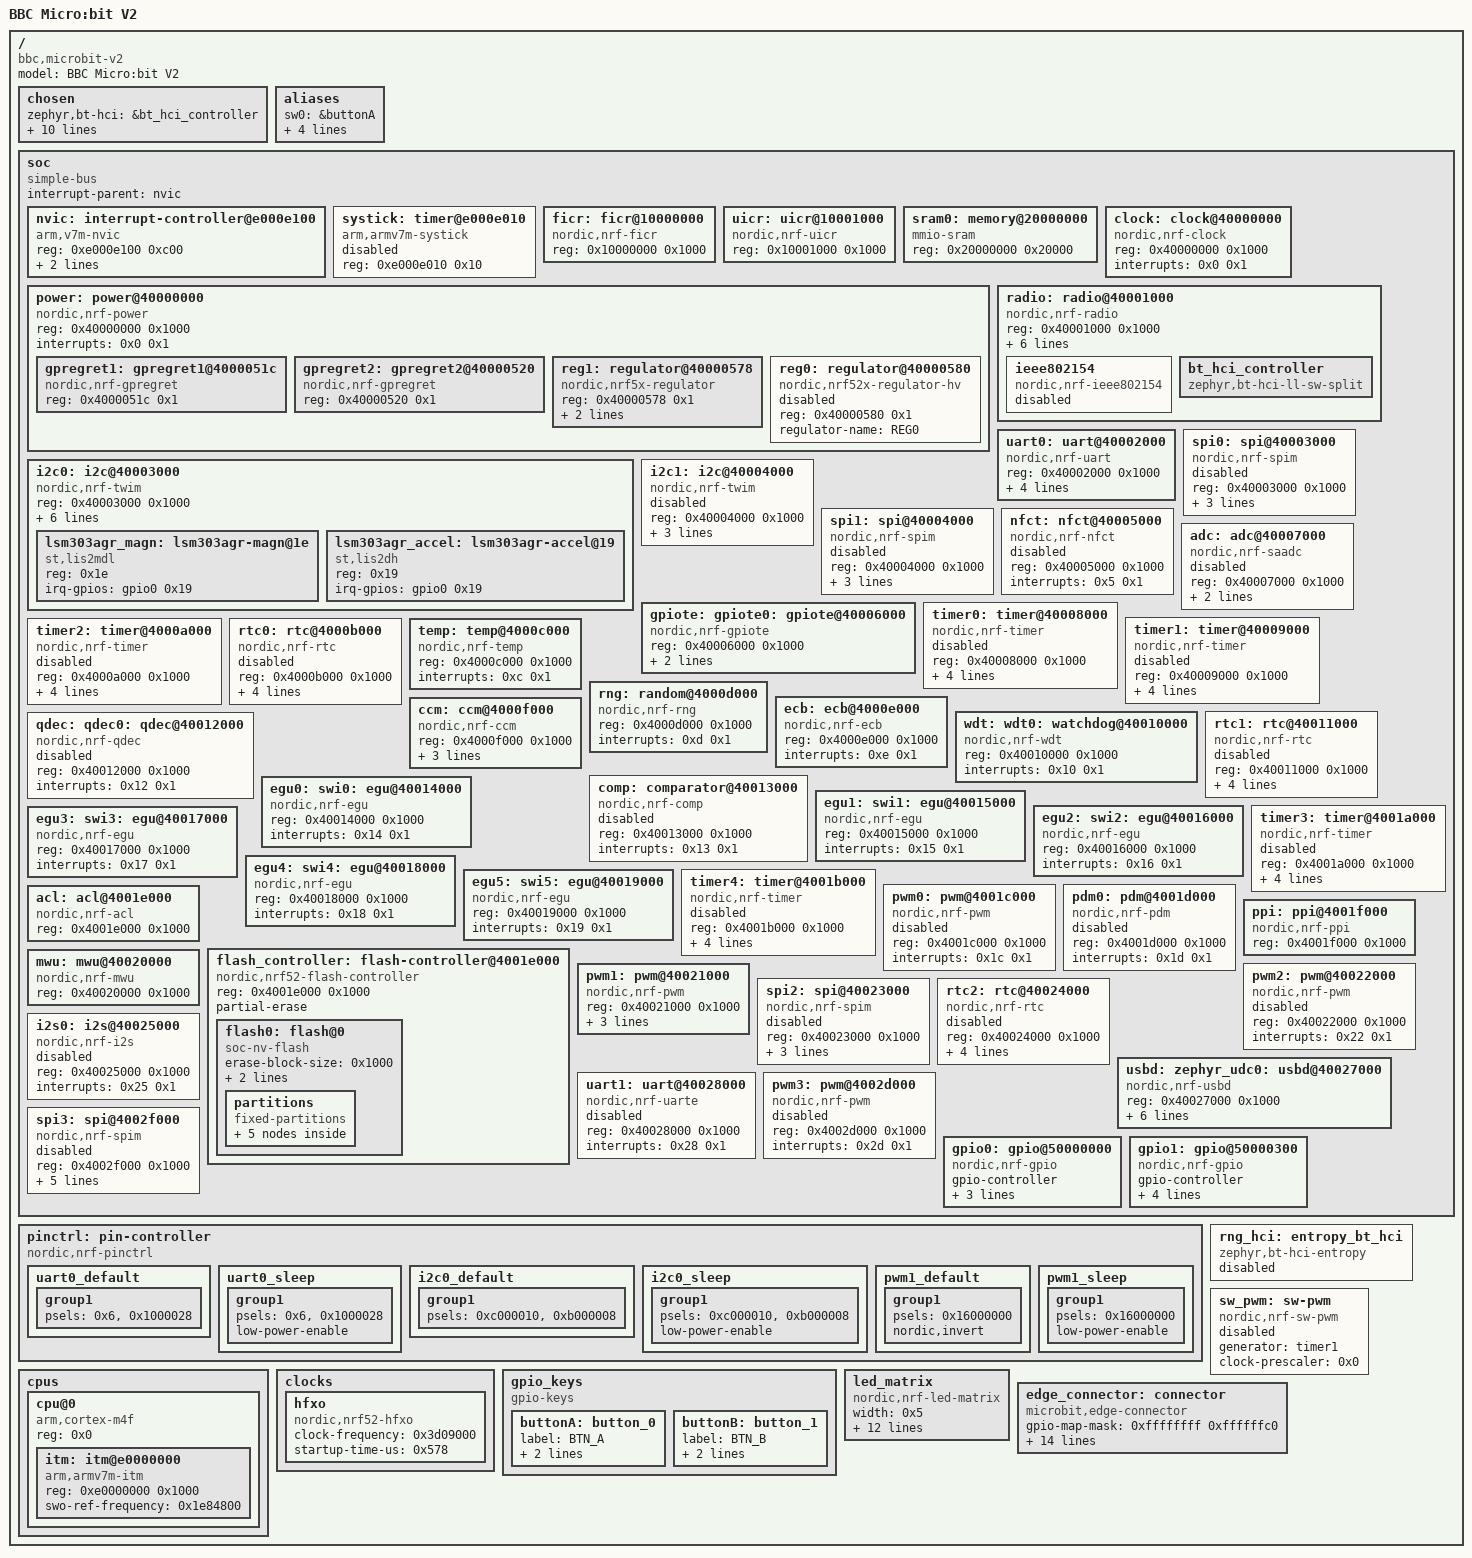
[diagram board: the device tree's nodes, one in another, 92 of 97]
/dts-v1/;

/* node '/' defined in zephyr/dts/common/skeleton.dtsi:9 */
/ {
	#address-cells = < 0x1 >;       /* in zephyr/dts/common/skeleton.dtsi:10 */
	#size-cells = < 0x1 >;          /* in zephyr/dts/common/skeleton.dtsi:11 */
	model = "BBC Micro:bit V2";     /* in zephyr/boards/bbc/microbit_v2/bbc_microbit_v2.dts:13 */
	compatible = "bbc,microbit-v2"; /* in zephyr/boards/bbc/microbit_v2/bbc_microbit_v2.dts:14 */

	/* node '/chosen' defined in zephyr/dts/common/skeleton.dtsi:13 */
	chosen {
		zephyr,bt-hci = &bt_hci_controller;          /* in zephyr/dts/arm/nordic/nrf52833.dtsi:14 */
		zephyr,entropy = &rng;                       /* in zephyr/dts/arm/nordic/nrf52833.dtsi:15 */
		zephyr,flash-controller = &flash_controller; /* in zephyr/dts/arm/nordic/nrf52833.dtsi:16 */
		zephyr,console = &uart0;                     /* in zephyr/boards/bbc/microbit_v2/bbc_microbit_v2.dts:26 */
		zephyr,shell-uart = &uart0;                  /* in zephyr/boards/bbc/microbit_v2/bbc_microbit_v2.dts:27 */
		zephyr,bt-mon-uart = &uart0;                 /* in zephyr/boards/bbc/microbit_v2/bbc_microbit_v2.dts:28 */
		zephyr,bt-c2h-uart = &uart0;                 /* in zephyr/boards/bbc/microbit_v2/bbc_microbit_v2.dts:29 */
		zephyr,sram = &sram0;                        /* in zephyr/boards/bbc/microbit_v2/bbc_microbit_v2.dts:30 */
		zephyr,flash = &flash0;                      /* in zephyr/boards/bbc/microbit_v2/bbc_microbit_v2.dts:31 */
		zephyr,code-partition = &slot0_partition;    /* in zephyr/boards/bbc/microbit_v2/bbc_microbit_v2.dts:32 */
		zephyr,display = &led_matrix;                /* in zephyr/boards/bbc/microbit_v2/bbc_microbit_v2.dts:33 */
	};

	/* node '/aliases' defined in zephyr/dts/common/skeleton.dtsi:15 */
	aliases {
		sw0 = &buttonA;            /* in zephyr/boards/bbc/microbit_v2/bbc_microbit_v2.dts:18 */
		sw1 = &buttonB;            /* in zephyr/boards/bbc/microbit_v2/bbc_microbit_v2.dts:19 */
		magn0 = &lsm303agr_magn;   /* in zephyr/boards/bbc/microbit_v2/bbc_microbit_v2.dts:20 */
		accel0 = &lsm303agr_accel; /* in zephyr/boards/bbc/microbit_v2/bbc_microbit_v2.dts:21 */
		watchdog0 = &wdt0;         /* in zephyr/boards/bbc/microbit_v2/bbc_microbit_v2.dts:22 */
	};

	/* node '/soc' defined in zephyr/dts/arm/armv7-m.dtsi:6 */
	soc {
		#address-cells = < 0x1 >;     /* in zephyr/dts/arm/armv7-m.dtsi:7 */
		#size-cells = < 0x1 >;        /* in zephyr/dts/arm/armv7-m.dtsi:8 */
		interrupt-parent = < &nvic >; /* in zephyr/dts/arm/armv7-m.dtsi:10 */
		ranges;                       /* in zephyr/dts/arm/armv7-m.dtsi:11 */
		compatible = "simple-bus";    /* in zephyr/dts/arm/nordic/nrf52833_qiaa.dtsi:21 */

		/* node '/soc/interrupt-controller@e000e100' defined in zephyr/dts/arm/armv7-m.dtsi:13 */
		nvic: interrupt-controller@e000e100 {
			#address-cells = < 0x1 >;            /* in zephyr/dts/arm/armv7-m.dtsi:14 */
			compatible = "arm,v7m-nvic";         /* in zephyr/dts/arm/armv7-m.dtsi:15 */
			reg = < 0xe000e100 0xc00 >;          /* in zephyr/dts/arm/armv7-m.dtsi:16 */
			interrupt-controller;                /* in zephyr/dts/arm/armv7-m.dtsi:17 */
			#interrupt-cells = < 0x2 >;          /* in zephyr/dts/arm/armv7-m.dtsi:18 */
			arm,num-irq-priority-bits = < 0x3 >; /* in zephyr/dts/arm/nordic/nrf52833.dtsi:577 */
			phandle = < 0x1 >;                   /* in zephyr/dts/arm/armv7-m.dtsi:10 */
		};

		/* node '/soc/timer@e000e010' defined in zephyr/dts/arm/armv7-m.dtsi:21 */
		systick: timer@e000e010 {
			compatible = "arm,armv7m-systick"; /* in zephyr/dts/arm/armv7-m.dtsi:22 */
			reg = < 0xe000e010 0x10 >;         /* in zephyr/dts/arm/armv7-m.dtsi:23 */
			status = "disabled";               /* in zephyr/dts/arm/nordic/nrf52833.dtsi:582 */
		};

		/* node '/soc/ficr@10000000' defined in zephyr/dts/arm/nordic/nrf52833.dtsi:48 */
		ficr: ficr@10000000 {
			compatible = "nordic,nrf-ficr"; /* in zephyr/dts/arm/nordic/nrf52833.dtsi:49 */
			reg = < 0x10000000 0x1000 >;    /* in zephyr/dts/arm/nordic/nrf52833.dtsi:50 */
			#nordic,ficr-cells = < 0x1 >;   /* in zephyr/dts/arm/nordic/nrf52833.dtsi:51 */
			status = "okay";                /* in zephyr/dts/arm/nordic/nrf52833.dtsi:52 */
		};

		/* node '/soc/uicr@10001000' defined in zephyr/dts/arm/nordic/nrf52833.dtsi:55 */
		uicr: uicr@10001000 {
			compatible = "nordic,nrf-uicr"; /* in zephyr/dts/arm/nordic/nrf52833.dtsi:56 */
			reg = < 0x10001000 0x1000 >;    /* in zephyr/dts/arm/nordic/nrf52833.dtsi:57 */
			status = "okay";                /* in zephyr/dts/arm/nordic/nrf52833.dtsi:58 */
		};

		/* node '/soc/memory@20000000' defined in zephyr/dts/arm/nordic/nrf52833.dtsi:61 */
		sram0: memory@20000000 {
			compatible = "mmio-sram";            /* in zephyr/dts/arm/nordic/nrf52833.dtsi:62 */
			#address-cells = < 0x1 >;            /* in zephyr/dts/arm/nordic/nrf52833.dtsi:63 */
			#size-cells = < 0x1 >;               /* in zephyr/dts/arm/nordic/nrf52833.dtsi:64 */
			reg = < 0x20000000 0x20000 >;        /* in zephyr/dts/arm/nordic/nrf52833_qiaa.dtsi:15 */
			ranges = < 0x0 0x20000000 0x20000 >; /* in zephyr/dts/arm/nordic/nrf52833_qiaa.dtsi:16 */
		};

		/* node '/soc/clock@40000000' defined in zephyr/dts/arm/nordic/nrf52833.dtsi:67 */
		clock: clock@40000000 {
			compatible = "nordic,nrf-clock"; /* in zephyr/dts/arm/nordic/nrf52833.dtsi:68 */
			reg = < 0x40000000 0x1000 >;     /* in zephyr/dts/arm/nordic/nrf52833.dtsi:69 */
			interrupts = < 0x0 0x1 >;        /* in zephyr/dts/arm/nordic/nrf52833.dtsi:70 */
			status = "okay";                 /* in zephyr/dts/arm/nordic/nrf52833.dtsi:71 */
		};

		/* node '/soc/power@40000000' defined in zephyr/dts/arm/nordic/nrf52833.dtsi:74 */
		power: power@40000000 {
			compatible = "nordic,nrf-power"; /* in zephyr/dts/arm/nordic/nrf52833.dtsi:75 */
			reg = < 0x40000000 0x1000 >;     /* in zephyr/dts/arm/nordic/nrf52833.dtsi:76 */
			interrupts = < 0x0 0x1 >;        /* in zephyr/dts/arm/nordic/nrf52833.dtsi:77 */
			status = "okay";                 /* in zephyr/dts/arm/nordic/nrf52833.dtsi:78 */
			#address-cells = < 0x1 >;        /* in zephyr/dts/arm/nordic/nrf52833.dtsi:79 */
			#size-cells = < 0x1 >;           /* in zephyr/dts/arm/nordic/nrf52833.dtsi:80 */

			/* node '/soc/power@40000000/gpregret1@4000051c' defined in zephyr/dts/arm/nordic/nrf52833.dtsi:82 */
			gpregret1: gpregret1@4000051c {
				#address-cells = < 0x1 >;           /* in zephyr/dts/arm/nordic/nrf52833.dtsi:83 */
				#size-cells = < 0x1 >;              /* in zephyr/dts/arm/nordic/nrf52833.dtsi:84 */
				compatible = "nordic,nrf-gpregret"; /* in zephyr/dts/arm/nordic/nrf52833.dtsi:85 */
				reg = < 0x4000051c 0x1 >;           /* in zephyr/dts/arm/nordic/nrf52833.dtsi:86 */
				status = "okay";                    /* in zephyr/dts/arm/nordic/nrf52833.dtsi:87 */
			};

			/* node '/soc/power@40000000/gpregret2@40000520' defined in zephyr/dts/arm/nordic/nrf52833.dtsi:90 */
			gpregret2: gpregret2@40000520 {
				#address-cells = < 0x1 >;           /* in zephyr/dts/arm/nordic/nrf52833.dtsi:91 */
				#size-cells = < 0x1 >;              /* in zephyr/dts/arm/nordic/nrf52833.dtsi:92 */
				compatible = "nordic,nrf-gpregret"; /* in zephyr/dts/arm/nordic/nrf52833.dtsi:93 */
				reg = < 0x40000520 0x1 >;           /* in zephyr/dts/arm/nordic/nrf52833.dtsi:94 */
				status = "okay";                    /* in zephyr/dts/arm/nordic/nrf52833.dtsi:95 */
			};

			/* node '/soc/power@40000000/regulator@40000578' defined in zephyr/dts/arm/nordic/nrf52833.dtsi:98 */
			reg1: regulator@40000578 {
				compatible = "nordic,nrf5x-regulator"; /* in zephyr/dts/arm/nordic/nrf52833.dtsi:99 */
				reg = < 0x40000578 0x1 >;              /* in zephyr/dts/arm/nordic/nrf52833.dtsi:100 */
				regulator-name = "REG1";               /* in zephyr/dts/arm/nordic/nrf52833.dtsi:101 */
				regulator-initial-mode = < 0x0 >;      /* in zephyr/dts/arm/nordic/nrf52833.dtsi:102 */
			};

			/* node '/soc/power@40000000/regulator@40000580' defined in zephyr/dts/arm/nordic/nrf52833.dtsi:105 */
			reg0: regulator@40000580 {
				compatible = "nordic,nrf52x-regulator-hv"; /* in zephyr/dts/arm/nordic/nrf52833.dtsi:106 */
				reg = < 0x40000580 0x1 >;                  /* in zephyr/dts/arm/nordic/nrf52833.dtsi:107 */
				regulator-name = "REG0";                   /* in zephyr/dts/arm/nordic/nrf52833.dtsi:108 */
				status = "disabled";                       /* in zephyr/dts/arm/nordic/nrf52833.dtsi:109 */
			};
		};

		/* node '/soc/radio@40001000' defined in zephyr/dts/arm/nordic/nrf52833.dtsi:113 */
		radio: radio@40001000 {
			compatible = "nordic,nrf-radio"; /* in zephyr/dts/arm/nordic/nrf52833.dtsi:114 */
			reg = < 0x40001000 0x1000 >;     /* in zephyr/dts/arm/nordic/nrf52833.dtsi:115 */
			interrupts = < 0x1 0x1 >;        /* in zephyr/dts/arm/nordic/nrf52833.dtsi:116 */
			status = "okay";                 /* in zephyr/dts/arm/nordic/nrf52833.dtsi:117 */
			dfe-supported;                   /* in zephyr/dts/arm/nordic/nrf52833.dtsi:118 */
			ieee802154-supported;            /* in zephyr/dts/arm/nordic/nrf52833.dtsi:119 */
			ble-2mbps-supported;             /* in zephyr/dts/arm/nordic/nrf52833.dtsi:120 */
			ble-coded-phy-supported;         /* in zephyr/dts/arm/nordic/nrf52833.dtsi:121 */
			tx-high-power-supported;         /* in zephyr/dts/arm/nordic/nrf52833.dtsi:122 */

			/* node '/soc/radio@40001000/ieee802154' defined in zephyr/dts/arm/nordic/nrf52833.dtsi:124 */
			ieee802154: ieee802154 {
				compatible = "nordic,nrf-ieee802154"; /* in zephyr/dts/arm/nordic/nrf52833.dtsi:125 */
				status = "disabled";                  /* in zephyr/dts/arm/nordic/nrf52833.dtsi:126 */
			};

			/* node '/soc/radio@40001000/bt_hci_controller' defined in zephyr/dts/arm/nordic/nrf52833.dtsi:132 */
			bt_hci_controller: bt_hci_controller {
				compatible = "zephyr,bt-hci-ll-sw-split"; /* in zephyr/dts/arm/nordic/nrf52833.dtsi:133 */
				status = "okay";                          /* in zephyr/dts/arm/nordic/nrf52833.dtsi:134 */
			};
		};

		/* node '/soc/uart@40002000' defined in zephyr/dts/arm/nordic/nrf52833.dtsi:138 */
		uart0: uart@40002000 {
			reg = < 0x40002000 0x1000 >;    /* in zephyr/dts/arm/nordic/nrf52833.dtsi:142 */
			interrupts = < 0x2 0x1 >;       /* in zephyr/dts/arm/nordic/nrf52833.dtsi:143 */
			compatible = "nordic,nrf-uart"; /* in zephyr/boards/bbc/microbit_v2/bbc_microbit_v2.dts:126 */
			status = "okay";                /* in zephyr/boards/bbc/microbit_v2/bbc_microbit_v2.dts:127 */
			current-speed = < 0x1c200 >;    /* in zephyr/boards/bbc/microbit_v2/bbc_microbit_v2.dts:128 */
			pinctrl-0 = < &uart0_default >; /* in zephyr/boards/bbc/microbit_v2/bbc_microbit_v2.dts:129 */
			pinctrl-1 = < &uart0_sleep >;   /* in zephyr/boards/bbc/microbit_v2/bbc_microbit_v2.dts:130 */
			pinctrl-names = "default",
			                "sleep";        /* in zephyr/boards/bbc/microbit_v2/bbc_microbit_v2.dts:131 */
		};

		/* node '/soc/i2c@40003000' defined in zephyr/dts/arm/nordic/nrf52833.dtsi:147 */
		i2c0: i2c@40003000 {
			#address-cells = < 0x1 >;       /* in zephyr/dts/arm/nordic/nrf52833.dtsi:156 */
			#size-cells = < 0x0 >;          /* in zephyr/dts/arm/nordic/nrf52833.dtsi:157 */
			reg = < 0x40003000 0x1000 >;    /* in zephyr/dts/arm/nordic/nrf52833.dtsi:158 */
			interrupts = < 0x3 0x1 >;       /* in zephyr/dts/arm/nordic/nrf52833.dtsi:159 */
			easydma-maxcnt-bits = < 0x10 >; /* in zephyr/dts/arm/nordic/nrf52833.dtsi:160 */
			zephyr,pm-device-runtime-auto;  /* in zephyr/dts/arm/nordic/nrf52833.dtsi:162 */
			compatible = "nordic,nrf-twim"; /* in zephyr/boards/bbc/microbit_v2/bbc_microbit_v2.dts:135 */
			status = "okay";                /* in zephyr/boards/bbc/microbit_v2/bbc_microbit_v2.dts:136 */
			clock-frequency = < 0x61a80 >;  /* in zephyr/boards/bbc/microbit_v2/bbc_microbit_v2.dts:137 */
			pinctrl-0 = < &i2c0_default >;  /* in zephyr/boards/bbc/microbit_v2/bbc_microbit_v2.dts:141 */
			pinctrl-1 = < &i2c0_sleep >;    /* in zephyr/boards/bbc/microbit_v2/bbc_microbit_v2.dts:142 */
			pinctrl-names = "default",
			                "sleep";        /* in zephyr/boards/bbc/microbit_v2/bbc_microbit_v2.dts:143 */

			/* node '/soc/i2c@40003000/lsm303agr-magn@1e' defined in zephyr/boards/bbc/microbit_v2/bbc_microbit_v2.dts:145 */
			lsm303agr_magn: lsm303agr-magn@1e {
				compatible = "st,lis2mdl",
				             "st,lsm303agr-magn"; /* in zephyr/boards/bbc/microbit_v2/bbc_microbit_v2.dts:146 */
				status = "okay";                  /* in zephyr/boards/bbc/microbit_v2/bbc_microbit_v2.dts:147 */
				reg = < 0x1e >;                   /* in zephyr/boards/bbc/microbit_v2/bbc_microbit_v2.dts:148 */
				irq-gpios = < &gpio0 0x19 0x0 >;  /* in zephyr/boards/bbc/microbit_v2/bbc_microbit_v2.dts:149 */
			};

			/* node '/soc/i2c@40003000/lsm303agr-accel@19' defined in zephyr/boards/bbc/microbit_v2/bbc_microbit_v2.dts:152 */
			lsm303agr_accel: lsm303agr-accel@19 {
				compatible = "st,lis2dh",
				             "st,lsm303agr-accel"; /* in zephyr/boards/bbc/microbit_v2/bbc_microbit_v2.dts:153 */
				status = "okay";                   /* in zephyr/boards/bbc/microbit_v2/bbc_microbit_v2.dts:154 */
				reg = < 0x19 >;                    /* in zephyr/boards/bbc/microbit_v2/bbc_microbit_v2.dts:155 */
				irq-gpios = < &gpio0 0x19 0x0 >;   /* in zephyr/boards/bbc/microbit_v2/bbc_microbit_v2.dts:156 */
			};
		};

		/* node '/soc/spi@40003000' defined in zephyr/dts/arm/nordic/nrf52833.dtsi:165 */
		spi0: spi@40003000 {
			compatible = "nordic,nrf-spim"; /* in zephyr/dts/arm/nordic/nrf52833.dtsi:173 */
			#address-cells = < 0x1 >;       /* in zephyr/dts/arm/nordic/nrf52833.dtsi:174 */
			#size-cells = < 0x0 >;          /* in zephyr/dts/arm/nordic/nrf52833.dtsi:175 */
			reg = < 0x40003000 0x1000 >;    /* in zephyr/dts/arm/nordic/nrf52833.dtsi:176 */
			interrupts = < 0x3 0x1 >;       /* in zephyr/dts/arm/nordic/nrf52833.dtsi:177 */
			max-frequency = < 0x7a1200 >;   /* in zephyr/dts/arm/nordic/nrf52833.dtsi:178 */
			easydma-maxcnt-bits = < 0x10 >; /* in zephyr/dts/arm/nordic/nrf52833.dtsi:179 */
			status = "disabled";            /* in zephyr/dts/arm/nordic/nrf52833.dtsi:180 */
		};

		/* node '/soc/i2c@40004000' defined in zephyr/dts/arm/nordic/nrf52833.dtsi:183 */
		i2c1: i2c@40004000 {
			compatible = "nordic,nrf-twim"; /* in zephyr/dts/arm/nordic/nrf52833.dtsi:191 */
			#address-cells = < 0x1 >;       /* in zephyr/dts/arm/nordic/nrf52833.dtsi:192 */
			#size-cells = < 0x0 >;          /* in zephyr/dts/arm/nordic/nrf52833.dtsi:193 */
			reg = < 0x40004000 0x1000 >;    /* in zephyr/dts/arm/nordic/nrf52833.dtsi:194 */
			interrupts = < 0x4 0x1 >;       /* in zephyr/dts/arm/nordic/nrf52833.dtsi:195 */
			easydma-maxcnt-bits = < 0x10 >; /* in zephyr/dts/arm/nordic/nrf52833.dtsi:196 */
			status = "disabled";            /* in zephyr/dts/arm/nordic/nrf52833.dtsi:197 */
			zephyr,pm-device-runtime-auto;  /* in zephyr/dts/arm/nordic/nrf52833.dtsi:198 */
		};

		/* node '/soc/spi@40004000' defined in zephyr/dts/arm/nordic/nrf52833.dtsi:201 */
		spi1: spi@40004000 {
			compatible = "nordic,nrf-spim"; /* in zephyr/dts/arm/nordic/nrf52833.dtsi:209 */
			#address-cells = < 0x1 >;       /* in zephyr/dts/arm/nordic/nrf52833.dtsi:210 */
			#size-cells = < 0x0 >;          /* in zephyr/dts/arm/nordic/nrf52833.dtsi:211 */
			reg = < 0x40004000 0x1000 >;    /* in zephyr/dts/arm/nordic/nrf52833.dtsi:212 */
			interrupts = < 0x4 0x1 >;       /* in zephyr/dts/arm/nordic/nrf52833.dtsi:213 */
			max-frequency = < 0x7a1200 >;   /* in zephyr/dts/arm/nordic/nrf52833.dtsi:214 */
			easydma-maxcnt-bits = < 0x10 >; /* in zephyr/dts/arm/nordic/nrf52833.dtsi:215 */
			status = "disabled";            /* in zephyr/dts/arm/nordic/nrf52833.dtsi:216 */
		};

		/* node '/soc/nfct@40005000' defined in zephyr/dts/arm/nordic/nrf52833.dtsi:219 */
		nfct: nfct@40005000 {
			compatible = "nordic,nrf-nfct"; /* in zephyr/dts/arm/nordic/nrf52833.dtsi:220 */
			reg = < 0x40005000 0x1000 >;    /* in zephyr/dts/arm/nordic/nrf52833.dtsi:221 */
			interrupts = < 0x5 0x1 >;       /* in zephyr/dts/arm/nordic/nrf52833.dtsi:222 */
			status = "disabled";            /* in zephyr/dts/arm/nordic/nrf52833.dtsi:223 */
		};

		/* node '/soc/gpiote@40006000' defined in zephyr/dts/arm/nordic/nrf52833.dtsi:226 */
		gpiote: gpiote0: gpiote@40006000 {
			compatible = "nordic,nrf-gpiote"; /* in zephyr/dts/arm/nordic/nrf52833.dtsi:227 */
			reg = < 0x40006000 0x1000 >;      /* in zephyr/dts/arm/nordic/nrf52833.dtsi:228 */
			interrupts = < 0x6 0x5 >;         /* in zephyr/dts/arm/nordic/nrf52833.dtsi:229 */
			instance = < 0x0 >;               /* in zephyr/dts/arm/nordic/nrf52833.dtsi:231 */
			status = "okay";                  /* in zephyr/boards/bbc/microbit_v2/bbc_microbit_v2.dts:106 */
			phandle = < 0x9 >;                /* in zephyr/dts/arm/nordic/nrf52833.dtsi:559 */
		};

		/* node '/soc/adc@40007000' defined in zephyr/dts/arm/nordic/nrf52833.dtsi:234 */
		adc: adc@40007000 {
			compatible = "nordic,nrf-saadc"; /* in zephyr/dts/arm/nordic/nrf52833.dtsi:235 */
			reg = < 0x40007000 0x1000 >;     /* in zephyr/dts/arm/nordic/nrf52833.dtsi:236 */
			interrupts = < 0x7 0x1 >;        /* in zephyr/dts/arm/nordic/nrf52833.dtsi:237 */
			status = "disabled";             /* in zephyr/dts/arm/nordic/nrf52833.dtsi:238 */
			#io-channel-cells = < 0x1 >;     /* in zephyr/dts/arm/nordic/nrf52833.dtsi:239 */
			zephyr,pm-device-runtime-auto;   /* in zephyr/dts/arm/nordic/nrf52833.dtsi:240 */
		};

		/* node '/soc/timer@40008000' defined in zephyr/dts/arm/nordic/nrf52833.dtsi:243 */
		timer0: timer@40008000 {
			compatible = "nordic,nrf-timer"; /* in zephyr/dts/arm/nordic/nrf52833.dtsi:244 */
			status = "disabled";             /* in zephyr/dts/arm/nordic/nrf52833.dtsi:245 */
			reg = < 0x40008000 0x1000 >;     /* in zephyr/dts/arm/nordic/nrf52833.dtsi:246 */
			cc-num = < 0x4 >;                /* in zephyr/dts/arm/nordic/nrf52833.dtsi:247 */
			max-bit-width = < 0x20 >;        /* in zephyr/dts/arm/nordic/nrf52833.dtsi:248 */
			interrupts = < 0x8 0x1 >;        /* in zephyr/dts/arm/nordic/nrf52833.dtsi:249 */
			prescaler = < 0x0 >;             /* in zephyr/dts/arm/nordic/nrf52833.dtsi:250 */
		};

		/* node '/soc/timer@40009000' defined in zephyr/dts/arm/nordic/nrf52833.dtsi:253 */
		timer1: timer@40009000 {
			compatible = "nordic,nrf-timer"; /* in zephyr/dts/arm/nordic/nrf52833.dtsi:254 */
			status = "disabled";             /* in zephyr/dts/arm/nordic/nrf52833.dtsi:255 */
			reg = < 0x40009000 0x1000 >;     /* in zephyr/dts/arm/nordic/nrf52833.dtsi:256 */
			cc-num = < 0x4 >;                /* in zephyr/dts/arm/nordic/nrf52833.dtsi:257 */
			max-bit-width = < 0x20 >;        /* in zephyr/dts/arm/nordic/nrf52833.dtsi:258 */
			interrupts = < 0x9 0x1 >;        /* in zephyr/dts/arm/nordic/nrf52833.dtsi:259 */
			prescaler = < 0x0 >;             /* in zephyr/dts/arm/nordic/nrf52833.dtsi:260 */
			phandle = < 0xa >;               /* in zephyr/dts/vendor/nordic/nrf_common.dtsi:42 */
		};

		/* node '/soc/timer@4000a000' defined in zephyr/dts/arm/nordic/nrf52833.dtsi:263 */
		timer2: timer@4000a000 {
			compatible = "nordic,nrf-timer"; /* in zephyr/dts/arm/nordic/nrf52833.dtsi:264 */
			status = "disabled";             /* in zephyr/dts/arm/nordic/nrf52833.dtsi:265 */
			reg = < 0x4000a000 0x1000 >;     /* in zephyr/dts/arm/nordic/nrf52833.dtsi:266 */
			cc-num = < 0x4 >;                /* in zephyr/dts/arm/nordic/nrf52833.dtsi:267 */
			max-bit-width = < 0x20 >;        /* in zephyr/dts/arm/nordic/nrf52833.dtsi:268 */
			interrupts = < 0xa 0x1 >;        /* in zephyr/dts/arm/nordic/nrf52833.dtsi:269 */
			prescaler = < 0x0 >;             /* in zephyr/dts/arm/nordic/nrf52833.dtsi:270 */
		};

		/* node '/soc/rtc@4000b000' defined in zephyr/dts/arm/nordic/nrf52833.dtsi:273 */
		rtc0: rtc@4000b000 {
			compatible = "nordic,nrf-rtc"; /* in zephyr/dts/arm/nordic/nrf52833.dtsi:274 */
			reg = < 0x4000b000 0x1000 >;   /* in zephyr/dts/arm/nordic/nrf52833.dtsi:275 */
			cc-num = < 0x3 >;              /* in zephyr/dts/arm/nordic/nrf52833.dtsi:276 */
			interrupts = < 0xb 0x1 >;      /* in zephyr/dts/arm/nordic/nrf52833.dtsi:277 */
			status = "disabled";           /* in zephyr/dts/arm/nordic/nrf52833.dtsi:278 */
			clock-frequency = < 0x8000 >;  /* in zephyr/dts/arm/nordic/nrf52833.dtsi:279 */
			prescaler = < 0x1 >;           /* in zephyr/dts/arm/nordic/nrf52833.dtsi:280 */
		};

		/* node '/soc/temp@4000c000' defined in zephyr/dts/arm/nordic/nrf52833.dtsi:283 */
		temp: temp@4000c000 {
			compatible = "nordic,nrf-temp"; /* in zephyr/dts/arm/nordic/nrf52833.dtsi:284 */
			reg = < 0x4000c000 0x1000 >;    /* in zephyr/dts/arm/nordic/nrf52833.dtsi:285 */
			interrupts = < 0xc 0x1 >;       /* in zephyr/dts/arm/nordic/nrf52833.dtsi:286 */
			status = "okay";                /* in zephyr/dts/arm/nordic/nrf52833.dtsi:287 */
		};

		/* node '/soc/random@4000d000' defined in zephyr/dts/arm/nordic/nrf52833.dtsi:290 */
		rng: random@4000d000 {
			compatible = "nordic,nrf-rng"; /* in zephyr/dts/arm/nordic/nrf52833.dtsi:291 */
			reg = < 0x4000d000 0x1000 >;   /* in zephyr/dts/arm/nordic/nrf52833.dtsi:292 */
			interrupts = < 0xd 0x1 >;      /* in zephyr/dts/arm/nordic/nrf52833.dtsi:293 */
			status = "okay";               /* in zephyr/dts/arm/nordic/nrf52833.dtsi:294 */
		};

		/* node '/soc/ecb@4000e000' defined in zephyr/dts/arm/nordic/nrf52833.dtsi:297 */
		ecb: ecb@4000e000 {
			compatible = "nordic,nrf-ecb"; /* in zephyr/dts/arm/nordic/nrf52833.dtsi:298 */
			reg = < 0x4000e000 0x1000 >;   /* in zephyr/dts/arm/nordic/nrf52833.dtsi:299 */
			interrupts = < 0xe 0x1 >;      /* in zephyr/dts/arm/nordic/nrf52833.dtsi:300 */
			status = "okay";               /* in zephyr/dts/arm/nordic/nrf52833.dtsi:301 */
		};

		/* node '/soc/ccm@4000f000' defined in zephyr/dts/arm/nordic/nrf52833.dtsi:304 */
		ccm: ccm@4000f000 {
			compatible = "nordic,nrf-ccm"; /* in zephyr/dts/arm/nordic/nrf52833.dtsi:305 */
			reg = < 0x4000f000 0x1000 >;   /* in zephyr/dts/arm/nordic/nrf52833.dtsi:306 */
			interrupts = < 0xf 0x1 >;      /* in zephyr/dts/arm/nordic/nrf52833.dtsi:307 */
			length-field-length-8-bits;    /* in zephyr/dts/arm/nordic/nrf52833.dtsi:308 */
			headermask-supported;          /* in zephyr/dts/arm/nordic/nrf52833.dtsi:309 */
			status = "okay";               /* in zephyr/dts/arm/nordic/nrf52833.dtsi:310 */
		};

		/* node '/soc/watchdog@40010000' defined in zephyr/dts/arm/nordic/nrf52833.dtsi:313 */
		wdt: wdt0: watchdog@40010000 {
			compatible = "nordic,nrf-wdt"; /* in zephyr/dts/arm/nordic/nrf52833.dtsi:314 */
			reg = < 0x40010000 0x1000 >;   /* in zephyr/dts/arm/nordic/nrf52833.dtsi:315 */
			interrupts = < 0x10 0x1 >;     /* in zephyr/dts/arm/nordic/nrf52833.dtsi:316 */
			status = "okay";               /* in zephyr/dts/arm/nordic/nrf52833.dtsi:317 */
		};

		/* node '/soc/rtc@40011000' defined in zephyr/dts/arm/nordic/nrf52833.dtsi:320 */
		rtc1: rtc@40011000 {
			compatible = "nordic,nrf-rtc"; /* in zephyr/dts/arm/nordic/nrf52833.dtsi:321 */
			reg = < 0x40011000 0x1000 >;   /* in zephyr/dts/arm/nordic/nrf52833.dtsi:322 */
			cc-num = < 0x4 >;              /* in zephyr/dts/arm/nordic/nrf52833.dtsi:323 */
			interrupts = < 0x11 0x1 >;     /* in zephyr/dts/arm/nordic/nrf52833.dtsi:324 */
			status = "disabled";           /* in zephyr/dts/arm/nordic/nrf52833.dtsi:325 */
			clock-frequency = < 0x8000 >;  /* in zephyr/dts/arm/nordic/nrf52833.dtsi:326 */
			prescaler = < 0x1 >;           /* in zephyr/dts/arm/nordic/nrf52833.dtsi:327 */
		};

		/* node '/soc/qdec@40012000' defined in zephyr/dts/arm/nordic/nrf52833.dtsi:330 */
		qdec: qdec0: qdec@40012000 {
			compatible = "nordic,nrf-qdec"; /* in zephyr/dts/arm/nordic/nrf52833.dtsi:331 */
			reg = < 0x40012000 0x1000 >;    /* in zephyr/dts/arm/nordic/nrf52833.dtsi:332 */
			interrupts = < 0x12 0x1 >;      /* in zephyr/dts/arm/nordic/nrf52833.dtsi:333 */
			status = "disabled";            /* in zephyr/dts/arm/nordic/nrf52833.dtsi:334 */
		};

		/* node '/soc/comparator@40013000' defined in zephyr/dts/arm/nordic/nrf52833.dtsi:337 */
		comp: comparator@40013000 {
			compatible = "nordic,nrf-comp"; /* in zephyr/dts/arm/nordic/nrf52833.dtsi:342 */
			reg = < 0x40013000 0x1000 >;    /* in zephyr/dts/arm/nordic/nrf52833.dtsi:343 */
			interrupts = < 0x13 0x1 >;      /* in zephyr/dts/arm/nordic/nrf52833.dtsi:344 */
			status = "disabled";            /* in zephyr/dts/arm/nordic/nrf52833.dtsi:345 */
		};

		/* node '/soc/egu@40014000' defined in zephyr/dts/arm/nordic/nrf52833.dtsi:348 */
		egu0: swi0: egu@40014000 {
			compatible = "nordic,nrf-egu",
			             "nordic,nrf-swi"; /* in zephyr/dts/arm/nordic/nrf52833.dtsi:349 */
			reg = < 0x40014000 0x1000 >;   /* in zephyr/dts/arm/nordic/nrf52833.dtsi:350 */
			interrupts = < 0x14 0x1 >;     /* in zephyr/dts/arm/nordic/nrf52833.dtsi:351 */
			status = "okay";               /* in zephyr/dts/arm/nordic/nrf52833.dtsi:352 */
		};

		/* node '/soc/egu@40015000' defined in zephyr/dts/arm/nordic/nrf52833.dtsi:355 */
		egu1: swi1: egu@40015000 {
			compatible = "nordic,nrf-egu",
			             "nordic,nrf-swi"; /* in zephyr/dts/arm/nordic/nrf52833.dtsi:356 */
			reg = < 0x40015000 0x1000 >;   /* in zephyr/dts/arm/nordic/nrf52833.dtsi:357 */
			interrupts = < 0x15 0x1 >;     /* in zephyr/dts/arm/nordic/nrf52833.dtsi:358 */
			status = "okay";               /* in zephyr/dts/arm/nordic/nrf52833.dtsi:359 */
		};

		/* node '/soc/egu@40016000' defined in zephyr/dts/arm/nordic/nrf52833.dtsi:362 */
		egu2: swi2: egu@40016000 {
			compatible = "nordic,nrf-egu",
			             "nordic,nrf-swi"; /* in zephyr/dts/arm/nordic/nrf52833.dtsi:363 */
			reg = < 0x40016000 0x1000 >;   /* in zephyr/dts/arm/nordic/nrf52833.dtsi:364 */
			interrupts = < 0x16 0x1 >;     /* in zephyr/dts/arm/nordic/nrf52833.dtsi:365 */
			status = "okay";               /* in zephyr/dts/arm/nordic/nrf52833.dtsi:366 */
		};

		/* node '/soc/egu@40017000' defined in zephyr/dts/arm/nordic/nrf52833.dtsi:369 */
		egu3: swi3: egu@40017000 {
			compatible = "nordic,nrf-egu",
			             "nordic,nrf-swi"; /* in zephyr/dts/arm/nordic/nrf52833.dtsi:370 */
			reg = < 0x40017000 0x1000 >;   /* in zephyr/dts/arm/nordic/nrf52833.dtsi:371 */
			interrupts = < 0x17 0x1 >;     /* in zephyr/dts/arm/nordic/nrf52833.dtsi:372 */
			status = "okay";               /* in zephyr/dts/arm/nordic/nrf52833.dtsi:373 */
		};

		/* node '/soc/egu@40018000' defined in zephyr/dts/arm/nordic/nrf52833.dtsi:376 */
		egu4: swi4: egu@40018000 {
			compatible = "nordic,nrf-egu",
			             "nordic,nrf-swi"; /* in zephyr/dts/arm/nordic/nrf52833.dtsi:377 */
			reg = < 0x40018000 0x1000 >;   /* in zephyr/dts/arm/nordic/nrf52833.dtsi:378 */
			interrupts = < 0x18 0x1 >;     /* in zephyr/dts/arm/nordic/nrf52833.dtsi:379 */
			status = "okay";               /* in zephyr/dts/arm/nordic/nrf52833.dtsi:380 */
		};

		/* node '/soc/egu@40019000' defined in zephyr/dts/arm/nordic/nrf52833.dtsi:383 */
		egu5: swi5: egu@40019000 {
			compatible = "nordic,nrf-egu",
			             "nordic,nrf-swi"; /* in zephyr/dts/arm/nordic/nrf52833.dtsi:384 */
			reg = < 0x40019000 0x1000 >;   /* in zephyr/dts/arm/nordic/nrf52833.dtsi:385 */
			interrupts = < 0x19 0x1 >;     /* in zephyr/dts/arm/nordic/nrf52833.dtsi:386 */
			status = "okay";               /* in zephyr/dts/arm/nordic/nrf52833.dtsi:387 */
		};

		/* node '/soc/timer@4001a000' defined in zephyr/dts/arm/nordic/nrf52833.dtsi:390 */
		timer3: timer@4001a000 {
			compatible = "nordic,nrf-timer"; /* in zephyr/dts/arm/nordic/nrf52833.dtsi:391 */
			status = "disabled";             /* in zephyr/dts/arm/nordic/nrf52833.dtsi:392 */
			reg = < 0x4001a000 0x1000 >;     /* in zephyr/dts/arm/nordic/nrf52833.dtsi:393 */
			cc-num = < 0x6 >;                /* in zephyr/dts/arm/nordic/nrf52833.dtsi:394 */
			max-bit-width = < 0x20 >;        /* in zephyr/dts/arm/nordic/nrf52833.dtsi:395 */
			interrupts = < 0x1a 0x1 >;       /* in zephyr/dts/arm/nordic/nrf52833.dtsi:396 */
			prescaler = < 0x0 >;             /* in zephyr/dts/arm/nordic/nrf52833.dtsi:397 */
		};

		/* node '/soc/timer@4001b000' defined in zephyr/dts/arm/nordic/nrf52833.dtsi:400 */
		timer4: timer@4001b000 {
			compatible = "nordic,nrf-timer"; /* in zephyr/dts/arm/nordic/nrf52833.dtsi:401 */
			status = "disabled";             /* in zephyr/dts/arm/nordic/nrf52833.dtsi:402 */
			reg = < 0x4001b000 0x1000 >;     /* in zephyr/dts/arm/nordic/nrf52833.dtsi:403 */
			cc-num = < 0x6 >;                /* in zephyr/dts/arm/nordic/nrf52833.dtsi:404 */
			max-bit-width = < 0x20 >;        /* in zephyr/dts/arm/nordic/nrf52833.dtsi:405 */
			interrupts = < 0x1b 0x1 >;       /* in zephyr/dts/arm/nordic/nrf52833.dtsi:406 */
			prescaler = < 0x0 >;             /* in zephyr/dts/arm/nordic/nrf52833.dtsi:407 */
			phandle = < 0xc >;               /* in zephyr/boards/bbc/microbit_v2/bbc_microbit_v2.dts:73 */
		};

		/* node '/soc/pwm@4001c000' defined in zephyr/dts/arm/nordic/nrf52833.dtsi:410 */
		pwm0: pwm@4001c000 {
			compatible = "nordic,nrf-pwm"; /* in zephyr/dts/arm/nordic/nrf52833.dtsi:411 */
			reg = < 0x4001c000 0x1000 >;   /* in zephyr/dts/arm/nordic/nrf52833.dtsi:412 */
			interrupts = < 0x1c 0x1 >;     /* in zephyr/dts/arm/nordic/nrf52833.dtsi:413 */
			status = "disabled";           /* in zephyr/dts/arm/nordic/nrf52833.dtsi:414 */
			#pwm-cells = < 0x3 >;          /* in zephyr/dts/arm/nordic/nrf52833.dtsi:415 */
			phandle = < 0xd >;             /* in zephyr/boards/bbc/microbit_v2/bbc_microbit_v2.dts:74 */
		};

		/* node '/soc/pdm@4001d000' defined in zephyr/dts/arm/nordic/nrf52833.dtsi:418 */
		pdm0: pdm@4001d000 {
			compatible = "nordic,nrf-pdm"; /* in zephyr/dts/arm/nordic/nrf52833.dtsi:419 */
			reg = < 0x4001d000 0x1000 >;   /* in zephyr/dts/arm/nordic/nrf52833.dtsi:420 */
			interrupts = < 0x1d 0x1 >;     /* in zephyr/dts/arm/nordic/nrf52833.dtsi:421 */
			status = "disabled";           /* in zephyr/dts/arm/nordic/nrf52833.dtsi:422 */
		};

		/* node '/soc/acl@4001e000' defined in zephyr/dts/arm/nordic/nrf52833.dtsi:425 */
		acl: acl@4001e000 {
			compatible = "nordic,nrf-acl"; /* in zephyr/dts/arm/nordic/nrf52833.dtsi:426 */
			reg = < 0x4001e000 0x1000 >;   /* in zephyr/dts/arm/nordic/nrf52833.dtsi:427 */
			status = "okay";               /* in zephyr/dts/arm/nordic/nrf52833.dtsi:428 */
		};

		/* node '/soc/flash-controller@4001e000' defined in zephyr/dts/arm/nordic/nrf52833.dtsi:431 */
		flash_controller: flash-controller@4001e000 {
			compatible = "nordic,nrf52-flash-controller"; /* in zephyr/dts/arm/nordic/nrf52833.dtsi:432 */
			reg = < 0x4001e000 0x1000 >;                  /* in zephyr/dts/arm/nordic/nrf52833.dtsi:433 */
			partial-erase;                                /* in zephyr/dts/arm/nordic/nrf52833.dtsi:434 */
			#address-cells = < 0x1 >;                     /* in zephyr/dts/arm/nordic/nrf52833.dtsi:436 */
			#size-cells = < 0x1 >;                        /* in zephyr/dts/arm/nordic/nrf52833.dtsi:437 */

			/* node '/soc/flash-controller@4001e000/flash@0' defined in zephyr/dts/arm/nordic/nrf52833.dtsi:439 */
			flash0: flash@0 {
				compatible = "soc-nv-flash";   /* in zephyr/dts/arm/nordic/nrf52833.dtsi:440 */
				erase-block-size = < 0x1000 >; /* in zephyr/dts/arm/nordic/nrf52833.dtsi:441 */
				write-block-size = < 0x4 >;    /* in zephyr/dts/arm/nordic/nrf52833.dtsi:442 */
				reg = < 0x0 0x80000 >;         /* in zephyr/dts/arm/nordic/nrf52833_qiaa.dtsi:11 */

				/* node '/soc/flash-controller@4001e000/flash@0/partitions' defined in zephyr/boards/bbc/microbit_v2/bbc_microbit_v2.dts:161 */
				partitions {
					compatible = "fixed-partitions"; /* in zephyr/boards/bbc/microbit_v2/bbc_microbit_v2.dts:162 */
					#address-cells = < 0x1 >;        /* in zephyr/boards/bbc/microbit_v2/bbc_microbit_v2.dts:163 */
					#size-cells = < 0x1 >;           /* in zephyr/boards/bbc/microbit_v2/bbc_microbit_v2.dts:164 */

					/* node '/soc/flash-controller@4001e000/flash@0/partitions/partition@0' defined in zephyr/boards/bbc/microbit_v2/bbc_microbit_v2.dts:166 */
					boot_partition: partition@0 {
						label = "mcuboot";    /* in zephyr/boards/bbc/microbit_v2/bbc_microbit_v2.dts:167 */
						reg = < 0x0 0xc000 >; /* in zephyr/boards/bbc/microbit_v2/bbc_microbit_v2.dts:168 */
					};

					/* node '/soc/flash-controller@4001e000/flash@0/partitions/partition@c000' defined in zephyr/boards/bbc/microbit_v2/bbc_microbit_v2.dts:171 */
					slot0_partition: partition@c000 {
						label = "image-0";        /* in zephyr/boards/bbc/microbit_v2/bbc_microbit_v2.dts:172 */
						reg = < 0xc000 0x32000 >; /* in zephyr/boards/bbc/microbit_v2/bbc_microbit_v2.dts:173 */
					};

					/* node '/soc/flash-controller@4001e000/flash@0/partitions/partition@3e000' defined in zephyr/boards/bbc/microbit_v2/bbc_microbit_v2.dts:176 */
					slot1_partition: partition@3e000 {
						label = "image-1";         /* in zephyr/boards/bbc/microbit_v2/bbc_microbit_v2.dts:177 */
						reg = < 0x3e000 0x32000 >; /* in zephyr/boards/bbc/microbit_v2/bbc_microbit_v2.dts:178 */
					};

					/* node '/soc/flash-controller@4001e000/flash@0/partitions/partition@70000' defined in zephyr/boards/bbc/microbit_v2/bbc_microbit_v2.dts:181 */
					scratch_partition: partition@70000 {
						label = "image-scratch";  /* in zephyr/boards/bbc/microbit_v2/bbc_microbit_v2.dts:182 */
						reg = < 0x70000 0xa000 >; /* in zephyr/boards/bbc/microbit_v2/bbc_microbit_v2.dts:183 */
					};

					/* node '/soc/flash-controller@4001e000/flash@0/partitions/partition@7a000' defined in zephyr/boards/bbc/microbit_v2/bbc_microbit_v2.dts:186 */
					storage_partition: partition@7a000 {
						label = "storage";        /* in zephyr/boards/bbc/microbit_v2/bbc_microbit_v2.dts:187 */
						reg = < 0x7a000 0x6000 >; /* in zephyr/boards/bbc/microbit_v2/bbc_microbit_v2.dts:188 */
					};
				};
			};
		};

		/* node '/soc/ppi@4001f000' defined in zephyr/dts/arm/nordic/nrf52833.dtsi:446 */
		ppi: ppi@4001f000 {
			compatible = "nordic,nrf-ppi"; /* in zephyr/dts/arm/nordic/nrf52833.dtsi:447 */
			reg = < 0x4001f000 0x1000 >;   /* in zephyr/dts/arm/nordic/nrf52833.dtsi:448 */
			status = "okay";               /* in zephyr/dts/arm/nordic/nrf52833.dtsi:449 */
		};

		/* node '/soc/mwu@40020000' defined in zephyr/dts/arm/nordic/nrf52833.dtsi:452 */
		mwu: mwu@40020000 {
			compatible = "nordic,nrf-mwu"; /* in zephyr/dts/arm/nordic/nrf52833.dtsi:453 */
			reg = < 0x40020000 0x1000 >;   /* in zephyr/dts/arm/nordic/nrf52833.dtsi:454 */
			status = "okay";               /* in zephyr/dts/arm/nordic/nrf52833.dtsi:455 */
		};

		/* node '/soc/pwm@40021000' defined in zephyr/dts/arm/nordic/nrf52833.dtsi:458 */
		pwm1: pwm@40021000 {
			compatible = "nordic,nrf-pwm"; /* in zephyr/dts/arm/nordic/nrf52833.dtsi:459 */
			reg = < 0x40021000 0x1000 >;   /* in zephyr/dts/arm/nordic/nrf52833.dtsi:460 */
			interrupts = < 0x21 0x1 >;     /* in zephyr/dts/arm/nordic/nrf52833.dtsi:461 */
			#pwm-cells = < 0x3 >;          /* in zephyr/dts/arm/nordic/nrf52833.dtsi:463 */
			status = "okay";               /* in zephyr/boards/bbc/microbit_v2/bbc_microbit_v2.dts:119 */
			pinctrl-0 = < &pwm1_default >; /* in zephyr/boards/bbc/microbit_v2/bbc_microbit_v2.dts:120 */
			pinctrl-1 = < &pwm1_sleep >;   /* in zephyr/boards/bbc/microbit_v2/bbc_microbit_v2.dts:121 */
			pinctrl-names = "default",
			                "sleep";       /* in zephyr/boards/bbc/microbit_v2/bbc_microbit_v2.dts:122 */
		};

		/* node '/soc/pwm@40022000' defined in zephyr/dts/arm/nordic/nrf52833.dtsi:466 */
		pwm2: pwm@40022000 {
			compatible = "nordic,nrf-pwm"; /* in zephyr/dts/arm/nordic/nrf52833.dtsi:467 */
			reg = < 0x40022000 0x1000 >;   /* in zephyr/dts/arm/nordic/nrf52833.dtsi:468 */
			interrupts = < 0x22 0x1 >;     /* in zephyr/dts/arm/nordic/nrf52833.dtsi:469 */
			status = "disabled";           /* in zephyr/dts/arm/nordic/nrf52833.dtsi:470 */
			#pwm-cells = < 0x3 >;          /* in zephyr/dts/arm/nordic/nrf52833.dtsi:471 */
		};

		/* node '/soc/spi@40023000' defined in zephyr/dts/arm/nordic/nrf52833.dtsi:474 */
		spi2: spi@40023000 {
			compatible = "nordic,nrf-spim"; /* in zephyr/dts/arm/nordic/nrf52833.dtsi:482 */
			#address-cells = < 0x1 >;       /* in zephyr/dts/arm/nordic/nrf52833.dtsi:483 */
			#size-cells = < 0x0 >;          /* in zephyr/dts/arm/nordic/nrf52833.dtsi:484 */
			reg = < 0x40023000 0x1000 >;    /* in zephyr/dts/arm/nordic/nrf52833.dtsi:485 */
			interrupts = < 0x23 0x1 >;      /* in zephyr/dts/arm/nordic/nrf52833.dtsi:486 */
			max-frequency = < 0x7a1200 >;   /* in zephyr/dts/arm/nordic/nrf52833.dtsi:487 */
			easydma-maxcnt-bits = < 0x10 >; /* in zephyr/dts/arm/nordic/nrf52833.dtsi:488 */
			status = "disabled";            /* in zephyr/dts/arm/nordic/nrf52833.dtsi:489 */
		};

		/* node '/soc/rtc@40024000' defined in zephyr/dts/arm/nordic/nrf52833.dtsi:492 */
		rtc2: rtc@40024000 {
			compatible = "nordic,nrf-rtc"; /* in zephyr/dts/arm/nordic/nrf52833.dtsi:493 */
			reg = < 0x40024000 0x1000 >;   /* in zephyr/dts/arm/nordic/nrf52833.dtsi:494 */
			cc-num = < 0x4 >;              /* in zephyr/dts/arm/nordic/nrf52833.dtsi:495 */
			interrupts = < 0x24 0x1 >;     /* in zephyr/dts/arm/nordic/nrf52833.dtsi:496 */
			status = "disabled";           /* in zephyr/dts/arm/nordic/nrf52833.dtsi:497 */
			clock-frequency = < 0x8000 >;  /* in zephyr/dts/arm/nordic/nrf52833.dtsi:498 */
			prescaler = < 0x1 >;           /* in zephyr/dts/arm/nordic/nrf52833.dtsi:499 */
		};

		/* node '/soc/i2s@40025000' defined in zephyr/dts/arm/nordic/nrf52833.dtsi:502 */
		i2s0: i2s@40025000 {
			compatible = "nordic,nrf-i2s"; /* in zephyr/dts/arm/nordic/nrf52833.dtsi:503 */
			#address-cells = < 0x1 >;      /* in zephyr/dts/arm/nordic/nrf52833.dtsi:504 */
			#size-cells = < 0x0 >;         /* in zephyr/dts/arm/nordic/nrf52833.dtsi:505 */
			reg = < 0x40025000 0x1000 >;   /* in zephyr/dts/arm/nordic/nrf52833.dtsi:506 */
			interrupts = < 0x25 0x1 >;     /* in zephyr/dts/arm/nordic/nrf52833.dtsi:507 */
			status = "disabled";           /* in zephyr/dts/arm/nordic/nrf52833.dtsi:508 */
		};

		/* node '/soc/usbd@40027000' defined in zephyr/dts/arm/nordic/nrf52833.dtsi:511 */
		usbd: zephyr_udc0: usbd@40027000 {
			reg = < 0x40027000 0x1000 >;    /* in zephyr/dts/arm/nordic/nrf52833.dtsi:513 */
			interrupts = < 0x27 0x1 >;      /* in zephyr/dts/arm/nordic/nrf52833.dtsi:514 */
			num-bidir-endpoints = < 0x1 >;  /* in zephyr/dts/arm/nordic/nrf52833.dtsi:515 */
			num-in-endpoints = < 0x7 >;     /* in zephyr/dts/arm/nordic/nrf52833.dtsi:516 */
			num-out-endpoints = < 0x7 >;    /* in zephyr/dts/arm/nordic/nrf52833.dtsi:517 */
			num-isoin-endpoints = < 0x1 >;  /* in zephyr/dts/arm/nordic/nrf52833.dtsi:518 */
			num-isoout-endpoints = < 0x1 >; /* in zephyr/dts/arm/nordic/nrf52833.dtsi:519 */
			compatible = "nordic,nrf-usbd"; /* in zephyr/boards/bbc/microbit_v2/bbc_microbit_v2.dts:194 */
			status = "okay";                /* in zephyr/boards/bbc/microbit_v2/bbc_microbit_v2.dts:195 */
		};

		/* node '/soc/uart@40028000' defined in zephyr/dts/arm/nordic/nrf52833.dtsi:523 */
		uart1: uart@40028000 {
			compatible = "nordic,nrf-uarte"; /* in zephyr/dts/arm/nordic/nrf52833.dtsi:524 */
			reg = < 0x40028000 0x1000 >;     /* in zephyr/dts/arm/nordic/nrf52833.dtsi:525 */
			interrupts = < 0x28 0x1 >;       /* in zephyr/dts/arm/nordic/nrf52833.dtsi:526 */
			status = "disabled";             /* in zephyr/dts/arm/nordic/nrf52833.dtsi:527 */
		};

		/* node '/soc/pwm@4002d000' defined in zephyr/dts/arm/nordic/nrf52833.dtsi:530 */
		pwm3: pwm@4002d000 {
			compatible = "nordic,nrf-pwm"; /* in zephyr/dts/arm/nordic/nrf52833.dtsi:531 */
			reg = < 0x4002d000 0x1000 >;   /* in zephyr/dts/arm/nordic/nrf52833.dtsi:532 */
			interrupts = < 0x2d 0x1 >;     /* in zephyr/dts/arm/nordic/nrf52833.dtsi:533 */
			status = "disabled";           /* in zephyr/dts/arm/nordic/nrf52833.dtsi:534 */
			#pwm-cells = < 0x3 >;          /* in zephyr/dts/arm/nordic/nrf52833.dtsi:535 */
		};

		/* node '/soc/spi@4002f000' defined in zephyr/dts/arm/nordic/nrf52833.dtsi:538 */
		spi3: spi@4002f000 {
			compatible = "nordic,nrf-spim"; /* in zephyr/dts/arm/nordic/nrf52833.dtsi:539 */
			#address-cells = < 0x1 >;       /* in zephyr/dts/arm/nordic/nrf52833.dtsi:540 */
			#size-cells = < 0x0 >;          /* in zephyr/dts/arm/nordic/nrf52833.dtsi:541 */
			reg = < 0x4002f000 0x1000 >;    /* in zephyr/dts/arm/nordic/nrf52833.dtsi:542 */
			interrupts = < 0x2f 0x1 >;      /* in zephyr/dts/arm/nordic/nrf52833.dtsi:543 */
			max-frequency = < 0x1e84800 >;  /* in zephyr/dts/arm/nordic/nrf52833.dtsi:544 */
			easydma-maxcnt-bits = < 0x10 >; /* in zephyr/dts/arm/nordic/nrf52833.dtsi:545 */
			rx-delay-supported;             /* in zephyr/dts/arm/nordic/nrf52833.dtsi:546 */
			rx-delay = < 0x2 >;             /* in zephyr/dts/arm/nordic/nrf52833.dtsi:547 */
			status = "disabled";            /* in zephyr/dts/arm/nordic/nrf52833.dtsi:548 */
		};

		/* node '/soc/gpio@50000000' defined in zephyr/dts/arm/nordic/nrf52833.dtsi:551 */
		gpio0: gpio@50000000 {
			compatible = "nordic,nrf-gpio";              /* in zephyr/dts/arm/nordic/nrf52833.dtsi:552 */
			gpio-controller;                             /* in zephyr/dts/arm/nordic/nrf52833.dtsi:553 */
			reg = < 0x50000000 0x200 0x50000500 0x300 >; /* in zephyr/dts/arm/nordic/nrf52833.dtsi:554 */
			#gpio-cells = < 0x2 >;                       /* in zephyr/dts/arm/nordic/nrf52833.dtsi:556 */
			port = < 0x0 >;                              /* in zephyr/dts/arm/nordic/nrf52833.dtsi:558 */
			gpiote-instance = < &gpiote >;               /* in zephyr/dts/arm/nordic/nrf52833.dtsi:559 */
			status = "okay";                             /* in zephyr/boards/bbc/microbit_v2/bbc_microbit_v2.dts:110 */
			phandle = < 0x6 >;                           /* in zephyr/boards/bbc/microbit_v2/bbc_microbit_v2.dts:149 */
		};

		/* node '/soc/gpio@50000300' defined in zephyr/dts/arm/nordic/nrf52833.dtsi:562 */
		gpio1: gpio@50000300 {
			compatible = "nordic,nrf-gpio";              /* in zephyr/dts/arm/nordic/nrf52833.dtsi:563 */
			gpio-controller;                             /* in zephyr/dts/arm/nordic/nrf52833.dtsi:564 */
			reg = < 0x50000300 0x200 0x50000800 0x300 >; /* in zephyr/dts/arm/nordic/nrf52833.dtsi:565 */
			#gpio-cells = < 0x2 >;                       /* in zephyr/dts/arm/nordic/nrf52833.dtsi:567 */
			ngpios = < 0xa >;                            /* in zephyr/dts/arm/nordic/nrf52833.dtsi:568 */
			port = < 0x1 >;                              /* in zephyr/dts/arm/nordic/nrf52833.dtsi:570 */
			gpiote-instance = < &gpiote >;               /* in zephyr/dts/arm/nordic/nrf52833.dtsi:571 */
			status = "okay";                             /* in zephyr/boards/bbc/microbit_v2/bbc_microbit_v2.dts:114 */
			phandle = < 0xb >;                           /* in zephyr/boards/bbc/microbit_v2/bbc_microbit_v2.dts:67 */
		};
	};

	/* node '/pin-controller' defined in zephyr/dts/vendor/nordic/nrf_common.dtsi:26 */
	pinctrl: pin-controller {
		compatible = "nordic,nrf-pinctrl"; /* in zephyr/dts/vendor/nordic/nrf_common.dtsi:31 */

		/* node '/pin-controller/uart0_default' defined in zephyr/boards/bbc/microbit_v2/bbc_microbit_v2-pinctrl.dtsi:7 */
		uart0_default: uart0_default {
			phandle = < 0x2 >; /* in zephyr/boards/bbc/microbit_v2/bbc_microbit_v2.dts:129 */

			/* node '/pin-controller/uart0_default/group1' defined in zephyr/boards/bbc/microbit_v2/bbc_microbit_v2-pinctrl.dtsi:8 */
			group1 {
				psels = < 0x6 >,
				        < 0x1000028 >; /* in zephyr/boards/bbc/microbit_v2/bbc_microbit_v2-pinctrl.dtsi:9 */
			};
		};

		/* node '/pin-controller/uart0_sleep' defined in zephyr/boards/bbc/microbit_v2/bbc_microbit_v2-pinctrl.dtsi:14 */
		uart0_sleep: uart0_sleep {
			phandle = < 0x3 >; /* in zephyr/boards/bbc/microbit_v2/bbc_microbit_v2.dts:130 */

			/* node '/pin-controller/uart0_sleep/group1' defined in zephyr/boards/bbc/microbit_v2/bbc_microbit_v2-pinctrl.dtsi:15 */
			group1 {
				psels = < 0x6 >,
				        < 0x1000028 >; /* in zephyr/boards/bbc/microbit_v2/bbc_microbit_v2-pinctrl.dtsi:16 */
				low-power-enable;      /* in zephyr/boards/bbc/microbit_v2/bbc_microbit_v2-pinctrl.dtsi:18 */
			};
		};

		/* node '/pin-controller/i2c0_default' defined in zephyr/boards/bbc/microbit_v2/bbc_microbit_v2-pinctrl.dtsi:22 */
		i2c0_default: i2c0_default {
			phandle = < 0x4 >; /* in zephyr/boards/bbc/microbit_v2/bbc_microbit_v2.dts:141 */

			/* node '/pin-controller/i2c0_default/group1' defined in zephyr/boards/bbc/microbit_v2/bbc_microbit_v2-pinctrl.dtsi:23 */
			group1 {
				psels = < 0xc000010 >,
				        < 0xb000008 >; /* in zephyr/boards/bbc/microbit_v2/bbc_microbit_v2-pinctrl.dtsi:24 */
			};
		};

		/* node '/pin-controller/i2c0_sleep' defined in zephyr/boards/bbc/microbit_v2/bbc_microbit_v2-pinctrl.dtsi:29 */
		i2c0_sleep: i2c0_sleep {
			phandle = < 0x5 >; /* in zephyr/boards/bbc/microbit_v2/bbc_microbit_v2.dts:142 */

			/* node '/pin-controller/i2c0_sleep/group1' defined in zephyr/boards/bbc/microbit_v2/bbc_microbit_v2-pinctrl.dtsi:30 */
			group1 {
				psels = < 0xc000010 >,
				        < 0xb000008 >; /* in zephyr/boards/bbc/microbit_v2/bbc_microbit_v2-pinctrl.dtsi:31 */
				low-power-enable;      /* in zephyr/boards/bbc/microbit_v2/bbc_microbit_v2-pinctrl.dtsi:33 */
			};
		};

		/* node '/pin-controller/pwm1_default' defined in zephyr/boards/bbc/microbit_v2/bbc_microbit_v2-pinctrl.dtsi:37 */
		pwm1_default: pwm1_default {
			phandle = < 0x7 >; /* in zephyr/boards/bbc/microbit_v2/bbc_microbit_v2.dts:120 */

			/* node '/pin-controller/pwm1_default/group1' defined in zephyr/boards/bbc/microbit_v2/bbc_microbit_v2-pinctrl.dtsi:38 */
			group1 {
				psels = < 0x16000000 >; /* in zephyr/boards/bbc/microbit_v2/bbc_microbit_v2-pinctrl.dtsi:39 */
				nordic,invert;          /* in zephyr/boards/bbc/microbit_v2/bbc_microbit_v2-pinctrl.dtsi:40 */
			};
		};

		/* node '/pin-controller/pwm1_sleep' defined in zephyr/boards/bbc/microbit_v2/bbc_microbit_v2-pinctrl.dtsi:44 */
		pwm1_sleep: pwm1_sleep {
			phandle = < 0x8 >; /* in zephyr/boards/bbc/microbit_v2/bbc_microbit_v2.dts:121 */

			/* node '/pin-controller/pwm1_sleep/group1' defined in zephyr/boards/bbc/microbit_v2/bbc_microbit_v2-pinctrl.dtsi:45 */
			group1 {
				psels = < 0x16000000 >; /* in zephyr/boards/bbc/microbit_v2/bbc_microbit_v2-pinctrl.dtsi:46 */
				low-power-enable;       /* in zephyr/boards/bbc/microbit_v2/bbc_microbit_v2-pinctrl.dtsi:47 */
			};
		};
	};

	/* node '/entropy_bt_hci' defined in zephyr/dts/vendor/nordic/nrf_common.dtsi:34 */
	rng_hci: entropy_bt_hci {
		compatible = "zephyr,bt-hci-entropy"; /* in zephyr/dts/vendor/nordic/nrf_common.dtsi:35 */
		status = "disabled";                  /* in zephyr/dts/vendor/nordic/nrf_common.dtsi:36 */
	};

	/* node '/sw-pwm' defined in zephyr/dts/vendor/nordic/nrf_common.dtsi:39 */
	sw_pwm: sw-pwm {
		compatible = "nordic,nrf-sw-pwm"; /* in zephyr/dts/vendor/nordic/nrf_common.dtsi:40 */
		status = "disabled";              /* in zephyr/dts/vendor/nordic/nrf_common.dtsi:41 */
		generator = < &timer1 >;          /* in zephyr/dts/vendor/nordic/nrf_common.dtsi:42 */
		clock-prescaler = < 0x0 >;        /* in zephyr/dts/vendor/nordic/nrf_common.dtsi:43 */
		#pwm-cells = < 0x3 >;             /* in zephyr/dts/vendor/nordic/nrf_common.dtsi:44 */
	};

	/* node '/cpus' defined in zephyr/dts/arm/nordic/nrf52833.dtsi:19 */
	cpus {
		#address-cells = < 0x1 >; /* in zephyr/dts/arm/nordic/nrf52833.dtsi:20 */
		#size-cells = < 0x0 >;    /* in zephyr/dts/arm/nordic/nrf52833.dtsi:21 */

		/* node '/cpus/cpu@0' defined in zephyr/dts/arm/nordic/nrf52833.dtsi:23 */
		cpu@0 {
			device_type = "cpu";           /* in zephyr/dts/arm/nordic/nrf52833.dtsi:24 */
			compatible = "arm,cortex-m4f"; /* in zephyr/dts/arm/nordic/nrf52833.dtsi:25 */
			reg = < 0x0 >;                 /* in zephyr/dts/arm/nordic/nrf52833.dtsi:26 */
			#address-cells = < 0x1 >;      /* in zephyr/dts/arm/nordic/nrf52833.dtsi:27 */
			#size-cells = < 0x1 >;         /* in zephyr/dts/arm/nordic/nrf52833.dtsi:28 */

			/* node '/cpus/cpu@0/itm@e0000000' defined in zephyr/dts/arm/nordic/nrf52833.dtsi:30 */
			itm: itm@e0000000 {
				compatible = "arm,armv7m-itm";     /* in zephyr/dts/arm/nordic/nrf52833.dtsi:31 */
				reg = < 0xe0000000 0x1000 >;       /* in zephyr/dts/arm/nordic/nrf52833.dtsi:32 */
				swo-ref-frequency = < 0x1e84800 >; /* in zephyr/dts/arm/nordic/nrf52833.dtsi:33 */
			};
		};
	};

	/* node '/clocks' defined in zephyr/dts/arm/nordic/nrf52833.dtsi:38 */
	clocks {

		/* node '/clocks/hfxo' defined in zephyr/dts/arm/nordic/nrf52833.dtsi:39 */
		hfxo: hfxo {
			compatible = "nordic,nrf52-hfxo"; /* in zephyr/dts/arm/nordic/nrf52833.dtsi:40 */
			clock-frequency = < 0x3d09000 >;  /* in zephyr/dts/arm/nordic/nrf52833.dtsi:41 */
			startup-time-us = < 0x578 >;      /* in zephyr/dts/arm/nordic/nrf52833.dtsi:42 */
			#clock-cells = < 0x0 >;           /* in zephyr/dts/arm/nordic/nrf52833.dtsi:43 */
		};
	};

	/* node '/gpio_keys' defined in zephyr/boards/bbc/microbit_v2/bbc_microbit_v2.dts:36 */
	gpio_keys {
		compatible = "gpio-keys"; /* in zephyr/boards/bbc/microbit_v2/bbc_microbit_v2.dts:37 */

		/* node '/gpio_keys/button_0' defined in zephyr/boards/bbc/microbit_v2/bbc_microbit_v2.dts:39 */
		buttonA: button_0 {
			label = "BTN_A";            /* in zephyr/boards/bbc/microbit_v2/bbc_microbit_v2.dts:40 */
			gpios = < &gpio0 0xe 0x1 >; /* in zephyr/boards/bbc/microbit_v2/bbc_microbit_v2.dts:41 */
			zephyr,code = < 0x1e >;     /* in zephyr/boards/bbc/microbit_v2/bbc_microbit_v2.dts:42 */
		};

		/* node '/gpio_keys/button_1' defined in zephyr/boards/bbc/microbit_v2/bbc_microbit_v2.dts:45 */
		buttonB: button_1 {
			label = "BTN_B";             /* in zephyr/boards/bbc/microbit_v2/bbc_microbit_v2.dts:46 */
			gpios = < &gpio0 0x17 0x1 >; /* in zephyr/boards/bbc/microbit_v2/bbc_microbit_v2.dts:47 */
			zephyr,code = < 0x30 >;      /* in zephyr/boards/bbc/microbit_v2/bbc_microbit_v2.dts:48 */
		};
	};

	/* node '/led_matrix' defined in zephyr/boards/bbc/microbit_v2/bbc_microbit_v2.dts:52 */
	led_matrix: led_matrix {
		compatible = "nordic,nrf-led-matrix";                                                           /* in zephyr/boards/bbc/microbit_v2/bbc_microbit_v2.dts:53 */
		status = "okay";                                                                                /* in zephyr/boards/bbc/microbit_v2/bbc_microbit_v2.dts:54 */
		width = < 0x5 >;                                                                                /* in zephyr/boards/bbc/microbit_v2/bbc_microbit_v2.dts:55 */
		height = < 0x5 >;                                                                               /* in zephyr/boards/bbc/microbit_v2/bbc_microbit_v2.dts:56 */
		pixel-mapping = [ 00 01 02 03 04 10 11 12 13 14 20 21 22 23 24 30 31 32 33 34 40 41 42 43 44 ]; /* in zephyr/boards/bbc/microbit_v2/bbc_microbit_v2.dts:57 */
		row-gpios = < &gpio0 0x15 0x0 >,
		            < &gpio0 0x16 0x0 >,
		            < &gpio0 0xf 0x0 >,
		            < &gpio0 0x18 0x0 >,
		            < &gpio0 0x13 0x0 >;                                                                /* in zephyr/boards/bbc/microbit_v2/bbc_microbit_v2.dts:62 */
		col-gpios = < &gpio0 0x1c 0x1 >,
		            < &gpio0 0xb 0x1 >,
		            < &gpio0 0x1f 0x1 >,
		            < &gpio1 0x5 0x1 >,
		            < &gpio0 0x1e 0x1 >;                                                                /* in zephyr/boards/bbc/microbit_v2/bbc_microbit_v2.dts:67 */
		refresh-frequency = < 0x32 >;                                                                   /* in zephyr/boards/bbc/microbit_v2/bbc_microbit_v2.dts:72 */
		timer = < &timer4 >;                                                                            /* in zephyr/boards/bbc/microbit_v2/bbc_microbit_v2.dts:73 */
		pwm = < &pwm0 >;                                                                                /* in zephyr/boards/bbc/microbit_v2/bbc_microbit_v2.dts:74 */
		pixel-group-size = < 0x4 >;                                                                     /* in zephyr/boards/bbc/microbit_v2/bbc_microbit_v2.dts:75 */
	};

	/* node '/connector' defined in zephyr/boards/bbc/microbit_v2/bbc_microbit_v2.dts:78 */
	edge_connector: connector {
		compatible = "microbit,edge-connector";    /* in zephyr/boards/bbc/microbit_v2/bbc_microbit_v2.dts:79 */
		#gpio-cells = < 0x2 >;                     /* in zephyr/boards/bbc/microbit_v2/bbc_microbit_v2.dts:80 */
		gpio-map-mask = < 0xffffffff 0xffffffc0 >; /* in zephyr/boards/bbc/microbit_v2/bbc_microbit_v2.dts:81 */
		gpio-map-pass-thru = < 0x0 0x3f >;         /* in zephyr/boards/bbc/microbit_v2/bbc_microbit_v2.dts:82 */
		gpio-map = < 0x0 0x0 &gpio0 0x2 0x0 >,
		           < 0x1 0x0 &gpio0 0x3 0x0 >,
		           < 0x2 0x0 &gpio0 0x4 0x0 >,
		           < 0x3 0x0 &gpio0 0x1f 0x0 >,
		           < 0x4 0x0 &gpio0 0x1c 0x0 >,
		           < 0x5 0x0 &gpio0 0xe 0x0 >,
		           < 0x6 0x0 &gpio1 0x5 0x0 >,
		           < 0x7 0x0 &gpio0 0xb 0x0 >,
		           < 0x8 0x0 &gpio0 0xa 0x0 >,
		           < 0x9 0x0 &gpio0 0x9 0x0 >,
		           < 0xa 0x0 &gpio0 0x1e 0x0 >,
		           < 0xb 0x0 &gpio0 0x17 0x0 >,
		           < 0xc 0x0 &gpio0 0xc 0x0 >,
		           < 0xd 0x0 &gpio0 0x11 0x0 >,
		           < 0xe 0x0 &gpio0 0x1 0x0 >,
		           < 0xf 0x0 &gpio0 0xd 0x0 >,
		           < 0x10 0x0 &gpio1 0x2 0x0 >,
		           < 0x13 0x0 &gpio0 0x1a 0x0 >,
		           < 0x14 0x0 &gpio1 0x0 0x0 >;    /* in zephyr/boards/bbc/microbit_v2/bbc_microbit_v2.dts:83 */
	};
};
